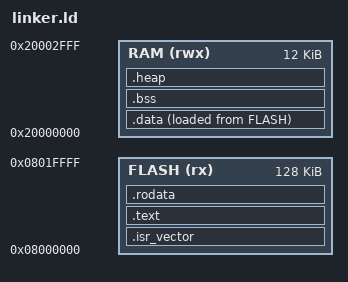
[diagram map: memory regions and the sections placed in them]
/* Linker script for STM32C071RB */
/* 128KB Flash, 12KB RAM */

MEMORY
{
    FLASH (rx)  : ORIGIN = 0x08000000, LENGTH = 128K
    RAM (rwx)   : ORIGIN = 0x20000000, LENGTH = 12K
}

ENTRY(Reset_Handler)

SECTIONS
{
    /* Vector table goes first in Flash */
    .isr_vector :
    {
        . = ALIGN(4);
        KEEP(*(.isr_vector))
        . = ALIGN(4);
    } > FLASH

    /* Code goes in Flash */
    .text :
    {
        . = ALIGN(4);
        *(.text)
        *(.text*)
        . = ALIGN(4);
    } > FLASH

    /* Constant data in Flash */
    .rodata :
    {
        . = ALIGN(4);
        *(.rodata)
        *(.rodata*)
        . = ALIGN(4);
    } > FLASH

    /* Initialized data (copied from Flash to RAM at startup) */
    .data :
    {
        . = ALIGN(4);
        _sdata = .;
        *(.data)
        *(.data*)
        . = ALIGN(4);
        _edata = .;
    } > RAM AT> FLASH

    /* Uninitialized data in RAM */
    .bss :
    {
        . = ALIGN(4);
        _sbss = .;
        __bss_start__ = _sbss;
        *(.bss)
        *(.bss*)
        *(COMMON)
        . = ALIGN(4);
        _ebss = .;
        __bss_end__ = _ebss;
    } > RAM
    
    /* Heap and stack */
    .heap :
    {
        . = ALIGN(4);
        end = .;
        _end = .;
        __end__ = .;
        . = . + 0x400;
    } > RAM
}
